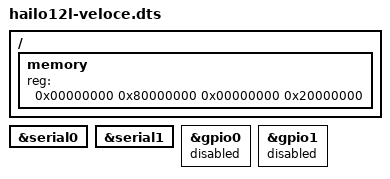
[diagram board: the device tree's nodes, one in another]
/dts-v1/;

#include "hailo12l-base.dtsi"

/ {
    memory {
        device_type = "memory";
        reg = <0x00000000 0x80000000 0x00000000 0x20000000>;
    };
};

&serial0 {
    status = "okay";
};

&serial1 {
    status = "okay";
};

&gpio0 {
    status = "disabled";
};

&gpio1 {
    status = "disabled";
};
